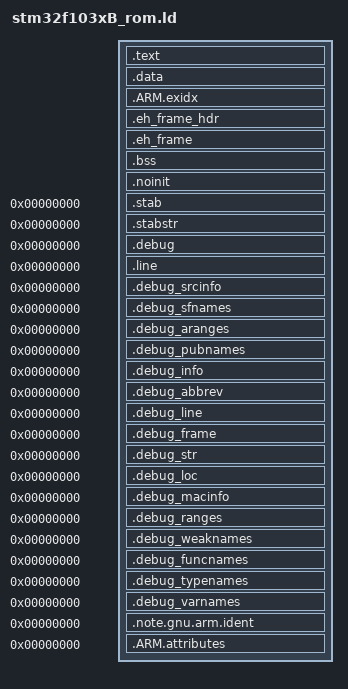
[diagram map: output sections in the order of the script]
 SECTIONS
 {
   /* Internal text space or external memory.  */
  .text   :
  {
    *(.vectors.cm3)
    KEEP(*(.vectors.cm3))
    *(.vectors.stm32f)
    KEEP(*(.vectors.stm32f))
    /* For data that needs to reside in the lower 64k of progmem.  */
    *(.progmem.gcc*)
    *(.progmem*)
    . = ALIGN(4);
     __trampolines_start = . ;
    /* The jump trampolines for the 16-bit limited relocs will reside here.  */
    *(.trampolines)
    *(.trampolines*)
     __trampolines_end = . ;
    /* For future tablejump instruction arrays for 3 byte pc devices.
       We don't relax jump/call instructions within these sections.  */
    *(.jumptables)
    *(.jumptables*)
    /* For code that needs to reside in the lower 128k progmem.  */
    *(.lowtext)
    *(.lowtext*)
     __ctors_start = . ;
     *(.ctors)
     __ctors_end = . ;
     __dtors_start = . ;
     *(.dtors)
     __dtors_end = . ;
    KEEP(SORT(*)(.ctors))
    KEEP(SORT(*)(.dtors))

    . = ALIGN(4);
    __preinit_array_start = .;
    KEEP (*(.preinit_array))
    __preinit_array_end = .;

    . = ALIGN(4);
    __init_array_start = .;
    KEEP (*(SORT(.init_array.*)))
    KEEP (*(.init_array))
    __init_array_end = .;

    /* Start here after reset.  */
    . = ALIGN(4);
    *(.init) 
    KEEP (*(.init))
    
    . = ALIGN(4);
    *(.text)
    *(.text.*)
    
    . = ALIGN(4);
    *(.fini)
    KEEP (*(.fini))
     _etext = . ;
  }  > text
  .data	  : AT (ADDR (.text) + SIZEOF (.text))
  {
    PROVIDE (__data_start = .) ;
     
    KEEP(*(.jcr))
    *(.got.plt) *(.got)
    *(.shdata)
    *(.data .data.*)
    *(.rodata)  /* We need to include .rodata here if gcc is used */
    *(.rodata*) /* with -fdata-sections.  */
    *(.gnu.linkonce.d*)
    . = ALIGN (8);
    *(.ram)
     _edata = . ;
    PROVIDE (__data_end = .) ;
  }  > data
  
  /* .ARM.exidx is sorted, so has to go in its own output section.  */
  __exidx_start = .;
  .ARM.exidx :
  {
     *(.ARM.exidx* .gnu.linkonce.armexidx.*)
  } >data
  __exidx_end = .;
  
  .eh_frame_hdr : ALIGN (4)
  {
    KEEP (*(.eh_frame_hdr))
  } >data
  .eh_frame : ALIGN (4)
  {
    KEEP (*(.eh_frame))
  } >data

  .bss   : AT (ADDR (.bss))
  {
    PROVIDE (__bss_start = .) ;
    *(.shbss)
    *(.bss .bss.* .gnu.linkonce.b.*)
    *(COMMON)
    . = ALIGN (8);
    *(.ram.b)
    *(COMMON)
     PROVIDE (__bss_end = .) ;

  }  > data
   __data_load_start = LOADADDR(.data);
   __data_load_end = __data_load_start + SIZEOF(.data);
  /* Global data not cleared after reset.  */
  .noinit  :
  {
     PROVIDE (__noinit_start = .) ;
    *(.noinit*)
     PROVIDE (__noinit_end = .) ;
     _end = . ;
     PROVIDE (__heap_start = .) ;
  }  > data
 
  PROVIDE (__stack_end = ORIGIN(data) + LENGTH(data)) ;

  .stab 0 (NOLOAD) : { *(.stab) }
  .stabstr 0 (NOLOAD) : { *(.stabstr) }
  /* DWARF debug sections.
   * Symbols in the DWARF debugging sections are relative to the beginning
   * of the section so we begin them at 0.  */
  /* DWARF 1 */
  .debug          0 : { *(.debug) }
  .line           0 : { *(.line) }
  /* GNU DWARF 1 extensions */
  .debug_srcinfo  0 : { *(.debug_srcinfo) }
  .debug_sfnames  0 : { *(.debug_sfnames) }
  /* DWARF 1.1 and DWARF 2 */
  .debug_aranges  0 : { *(.debug_aranges) }
  .debug_pubnames 0 : { *(.debug_pubnames) }
  /* DWARF 2 */
  .debug_info     0 : { *(.debug_info .gnu.linkonce.wi.*) }
  .debug_abbrev   0 : { *(.debug_abbrev) }
  .debug_line     0 : { *(.debug_line) }
  .debug_frame    0 : { *(.debug_frame) }
  .debug_str      0 : { *(.debug_str) }
  .debug_loc      0 : { *(.debug_loc) }
  .debug_macinfo  0 : { *(.debug_macinfo) }
  /* DWARF 2.1 */
  .debug_ranges   0 : { *(.debug_ranges) }
  /* SGI/MIPS DWARF 2 extensions */
  .debug_weaknames 0 : { *(.debug_weaknames) }
  .debug_funcnames 0 : { *(.debug_funcnames) }
  .debug_typenames 0 : { *(.debug_typenames) }
  .debug_varnames  0 : { *(.debug_varnames) }

  .note.gnu.arm.ident 0 : { KEEP (*(.note.gnu.arm.ident)) }
  .ARM.attributes 0 : { KEEP (*(.ARM.attributes)) }
  /DISCARD/ : { *(.note.GNU-stack) }

 }
/*========== end of file ==========*/
